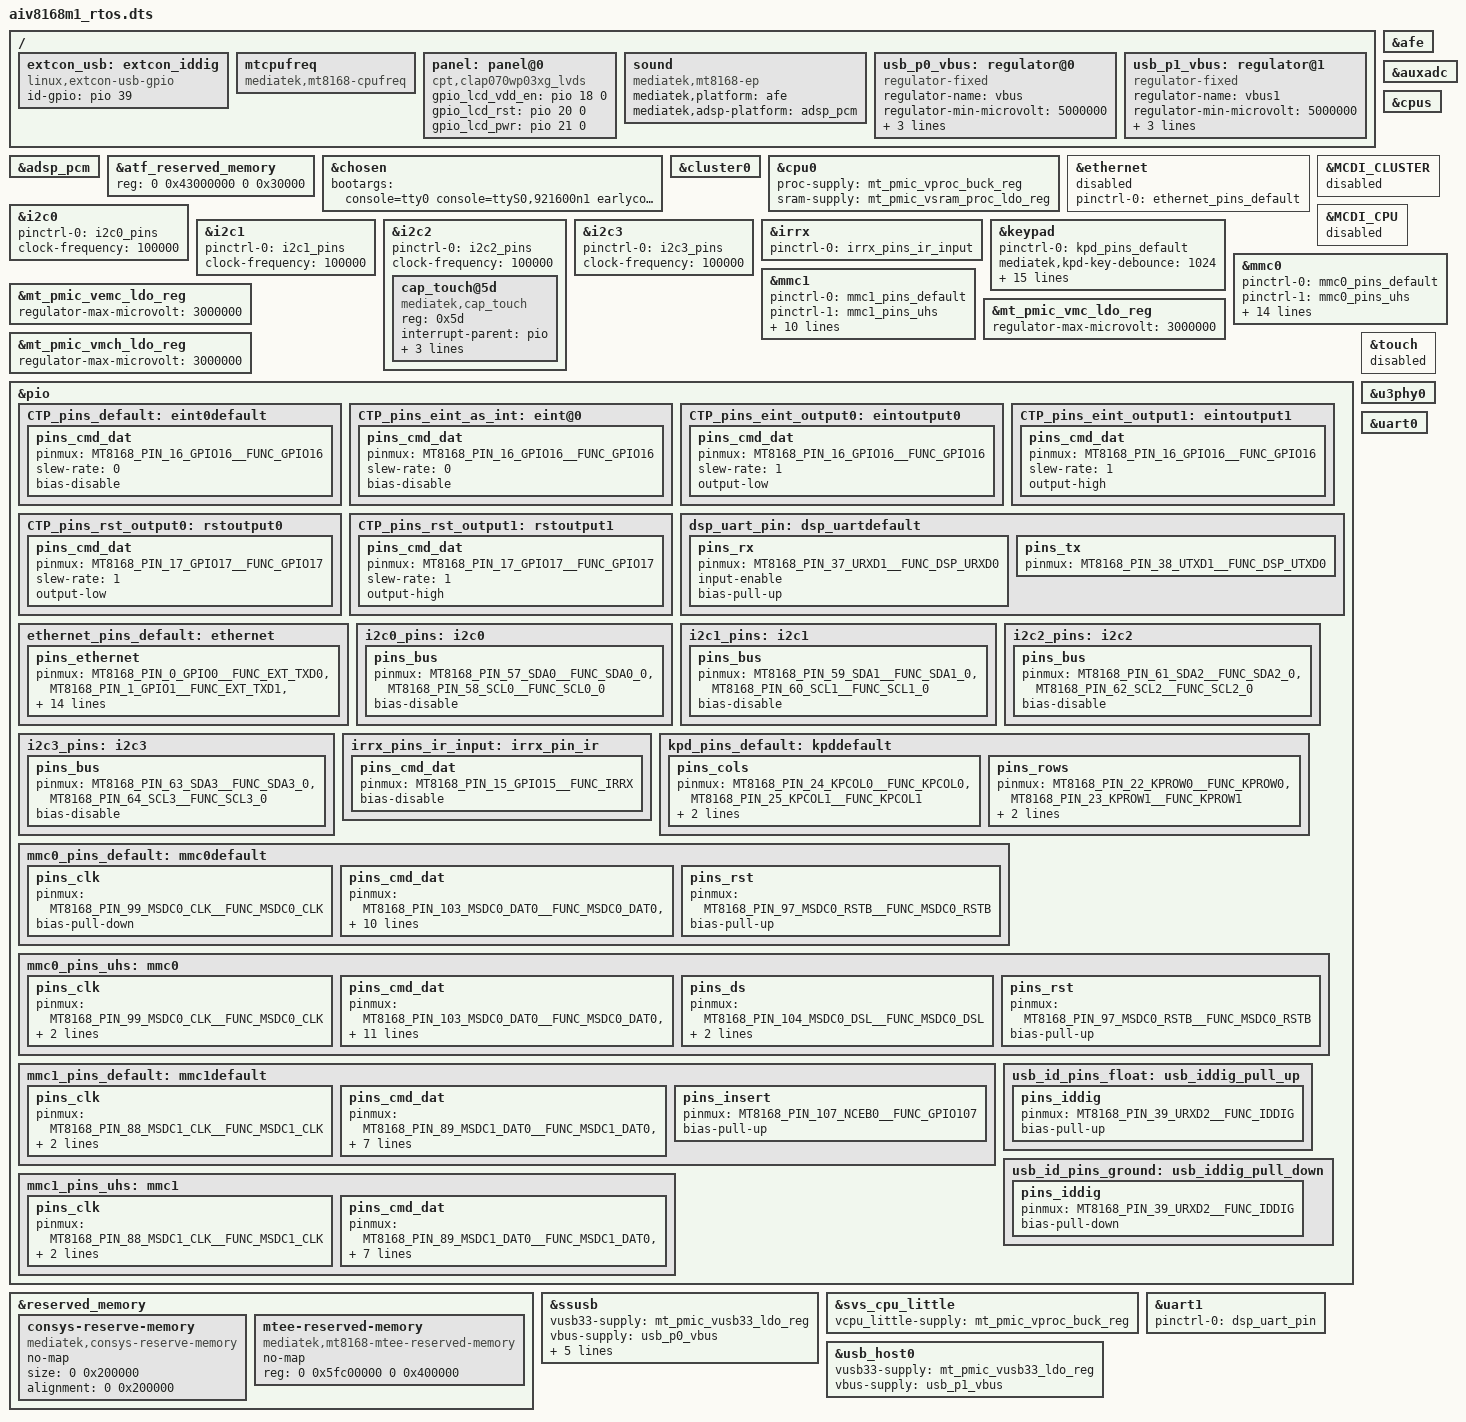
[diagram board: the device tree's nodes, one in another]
/*
 * Copyright (c) 2019 MediaTek Inc.
 *
 * This program is free software; you can redistribute it and/or modify
 * it under the terms of the GNU General Public License version 2 as
 * published by the Free Software Foundation.
 *
 * This program is distributed in the hope that it will be useful,
 * MERCHANTABILITY or FITNESS FOR A PARTICULAR PURPOSE.  See the
 * GNU General Public License for more details.
 */

/dts-v1/;
#include <dt-bindings/gpio/gpio.h>
#include "mt8168.dtsi"
#include "mt6357.dtsi"

/ {
	extcon_usb: extcon_iddig {
		compatible = "linux,extcon-usb-gpio";
		id-gpio = <&pio 39 GPIO_ACTIVE_HIGH>;
	};

	mtcpufreq {
		compatible = "mediatek,mt8168-cpufreq";
	};

	panel: panel@0 {
		compatible = "cpt,clap070wp03xg_lvds";
		gpio_lcd_vdd_en = <&pio 18 0>;
		gpio_lcd_rst = <&pio 20 0>;
		gpio_lcd_pwr = <&pio 21 0>;
		/*reg-lcm-supply = <&mt6392_vgp2_reg>;*/
	};

	sound: sound {
		compatible = "mediatek,mt8168-ep";
		mediatek,platform = <&afe>;
		mediatek,adsp-platform = <&adsp_pcm>;
		status = "okay";
	};

	usb_p0_vbus: regulator@0 {
		compatible = "regulator-fixed";
		regulator-name = "vbus";
		regulator-min-microvolt = <5000000>;
		regulator-max-microvolt = <5000000>;
		gpio = <&pio 40 GPIO_ACTIVE_HIGH>;
		enable-active-high;
	};

	usb_p1_vbus: regulator@1 {
		compatible = "regulator-fixed";
		regulator-name = "vbus1";
		regulator-min-microvolt = <5000000>;
		regulator-max-microvolt = <5000000>;
		enable-active-high;
		regulator-always-on;
	};
};

&adsp_pcm {
	status = "okay";
};

&afe {
	status = "okay";
};

&atf_reserved_memory {
	reg = <0 0x43000000 0 0x30000>;
};

&auxadc {
	status = "okay";
};

&chosen {
	bootargs = "console=tty0 console=ttyS0,921600n1 \
		    earlycon=uart8250,mmio32,0x11002000 vmalloc=496M \
		    clk_ignore_unused pd_ignore_unused \
		    skip_initramfs rootwait ro init=/sbin/init \
		    root=PARTUUID=936e1662-2b63-435d-859d-1b9e5a838335 \
		    boot_reason=0";
};

&cluster0 {
	/delete-node/ core1;
	/delete-node/ core2;
	/delete-node/ core3;
};

&cpus {
	/delete-node/ cpu@1;
	/delete-node/ cpu@2;
	/delete-node/ cpu@3;
};

&cpu0 {
	proc-supply = <&mt_pmic_vproc_buck_reg>;
	sram-supply = <&mt_pmic_vsram_proc_ldo_reg>;
};

&ethernet {
	status = "disabled";
	pinctrl-names = "default";
	pinctrl-0 = <&ethernet_pins_default>;
};

&i2c0 {
	pinctrl-names = "default";
	pinctrl-0 = <&i2c0_pins>;
	clock-frequency = <100000>;
	status = "okay";
};

&i2c1 {
	pinctrl-names = "default";
	pinctrl-0 = <&i2c1_pins>;
	clock-frequency = <100000>;
	status = "okay";
};

&i2c2 {
	pinctrl-names = "default";
	pinctrl-0 = <&i2c2_pins>;
	clock-frequency = <100000>;
	status = "okay";

	cap_touch@5d {
		compatible = "mediatek,cap_touch";
		reg = <0x5d>;
		interrupt-parent = <&pio>;
		interrupts = <16 IRQ_TYPE_EDGE_FALLING>;
		int-gpio = <&pio 16 0>;
		rst-gpio = <&pio 17 0>;
	};
};

&i2c3 {
	pinctrl-names = "default";
	pinctrl-0 = <&i2c3_pins>;
	clock-frequency = <100000>;
	status = "okay";
};

&irrx {
	pinctrl-names = "default";
	pinctrl-0 = <&irrx_pins_ir_input>;
	status = "okay";
};

&keypad {
	pinctrl-names = "default";
	pinctrl-0 = <&kpd_pins_default>;
	status = "okay";
	mediatek,kpd-key-debounce = <1024>;
	mediatek,kpd-sw-pwrkey = <116>;
	mediatek,kpd-hw-pwrkey = <1>;
	mediatek,kpd-sw-rstkey  = <114>;
	mediatek,kpd-hw-rstkey = <3>;
	mediatek,kpd-use-extend-type = <0>;
	/*HW Keycode [0~3] -> Linux Keycode*/
	mediatek,kpd-hw-map-num = <72>;
	mediatek,kpd-hw-init-map =
			<115 0 0 0 0 0 0 0 0 0 0 0 0
			 0 0 0 0 0 0 0 0 0 0 0 0 0 0 0 0 0 0 0 0 0 0 0 0
			 0 0 0 0 0 0 0 0 0 0 0 0 0 0 0 0 0 0 0 0 0 0 0 0
			 0 0 0 0 0 0 0 0 0 0 0 >;
	mediatek,kpd-pwrkey-eint-gpio = <0>;
	mediatek,kpd-pwkey-gpio-din  = <0>;
	mediatek,kpd-hw-dl-key0 = <0>;
	mediatek,kpd-hw-dl-key1 = <3>;
	mediatek,kpd-hw-dl-key2 = <1>;
	mediatek,kpd-hw-recovery-key = <0>;
	mediatek,kpd-hw-factory-key  = <3>;
};

&MCDI_CLUSTER {
	status = "disabled";
};

&MCDI_CPU {
	status = "disabled";
};

&mmc0 {
	status = "okay";
	pinctrl-names = "default", "state_uhs";
	pinctrl-0 = <&mmc0_pins_default>;
	pinctrl-1 = <&mmc0_pins_uhs>;
	bus-width = <8>;
	max-frequency = <200000000>;
	cap-mmc-highspeed;
	mmc-hs200-1_8v;
	mmc-hs400-1_8v;
	hs400-ds-delay = <0x12012>;
	vmmc-supply = <&mt_pmic_vemc_ldo_reg>;
	vqmmc-supply = <&mt_pmic_vio18_ldo_reg>;
	assigned-clocks = <&topckgen CLK_TOP_MSDC50_0_SEL>;
	assigned-clock-parents = <&topckgen CLK_TOP_MSDCPLL>;
	non-removable;
	no-sd;
	no-sdio;
};

&mmc1 {
	status = "okay";
	pinctrl-names = "default", "state_uhs";
	pinctrl-0 = <&mmc1_pins_default>;
	pinctrl-1 = <&mmc1_pins_uhs>;
	bus-width = <4>;
	max-frequency = <200000000>;
	cap-sd-highspeed;
	sd-uhs-sdr50;
	sd-uhs-sdr104;
	cd-gpios = <&pio 107 GPIO_ACTIVE_LOW>;
	vmmc-supply = <&mt_pmic_vmch_ldo_reg>;
	vqmmc-supply = <&mt_pmic_vmc_ldo_reg>;
	no-mmc;
	no-sdio;
};

&mt_pmic_vemc_ldo_reg {
	regulator-max-microvolt = <3000000>;
};

&mt_pmic_vmc_ldo_reg {
	regulator-max-microvolt = <3000000>;
};

&mt_pmic_vmch_ldo_reg {
	regulator-max-microvolt = <3000000>;
};

&pio {
	pinctrl-names = "default";

	CTP_pins_default: eint0default {
		pins_cmd_dat {
			pinmux = <MT8168_PIN_16_GPIO16__FUNC_GPIO16>;
			slew-rate = <0>;
			bias-disable;
		};
	};

	CTP_pins_eint_as_int: eint@0 {
		pins_cmd_dat {
			pinmux = <MT8168_PIN_16_GPIO16__FUNC_GPIO16>;
			slew-rate = <0>;
			bias-disable;
		};
	};

	CTP_pins_eint_output0: eintoutput0 {
		pins_cmd_dat {
			pinmux = <MT8168_PIN_16_GPIO16__FUNC_GPIO16>;
			slew-rate = <1>;
			output-low;
		};
	};

	CTP_pins_eint_output1: eintoutput1 {
		pins_cmd_dat {
			pinmux = <MT8168_PIN_16_GPIO16__FUNC_GPIO16>;
			slew-rate = <1>;
			output-high;
		};
	};

	CTP_pins_rst_output0: rstoutput0 {
		pins_cmd_dat {
			pinmux = <MT8168_PIN_17_GPIO17__FUNC_GPIO17>;
			slew-rate = <1>;
			output-low;
		};
	};

	CTP_pins_rst_output1: rstoutput1 {
		pins_cmd_dat {
			pinmux = <MT8168_PIN_17_GPIO17__FUNC_GPIO17>;
			slew-rate = <1>;
			output-high;
		};
	};

	dsp_uart_pin: dsp_uartdefault {
		pins_rx {
			pinmux = <MT8168_PIN_37_URXD1__FUNC_DSP_URXD0>;
			input-enable;
			bias-pull-up;
		};
		pins_tx {
			pinmux = <MT8168_PIN_38_UTXD1__FUNC_DSP_UTXD0>;
		};
	};

	ethernet_pins_default: ethernet {
		pins_ethernet {
			pinmux = <MT8168_PIN_0_GPIO0__FUNC_EXT_TXD0>,
				 <MT8168_PIN_1_GPIO1__FUNC_EXT_TXD1>,
				 <MT8168_PIN_2_GPIO2__FUNC_EXT_TXD2>,
				 <MT8168_PIN_3_GPIO3__FUNC_EXT_TXD3>,
				 <MT8168_PIN_4_GPIO4__FUNC_EXT_TXC>,
				 <MT8168_PIN_5_GPIO5__FUNC_EXT_RXER>,
				 <MT8168_PIN_6_GPIO6__FUNC_EXT_RXC>,
				 <MT8168_PIN_7_GPIO7__FUNC_EXT_RXDV>,
				 <MT8168_PIN_8_GPIO8__FUNC_EXT_RXD0>,
				 <MT8168_PIN_9_GPIO9__FUNC_EXT_RXD1>,
				 <MT8168_PIN_10_GPIO10__FUNC_EXT_RXD2>,
				 <MT8168_PIN_11_GPIO11__FUNC_EXT_RXD3>,
				 <MT8168_PIN_12_GPIO12__FUNC_EXT_TXEN>,
				 <MT8168_PIN_13_GPIO13__FUNC_EXT_COL>,
				 <MT8168_PIN_14_GPIO14__FUNC_EXT_MDIO>,
				 <MT8168_PIN_15_GPIO15__FUNC_EXT_MDC>;
		};
	};

	i2c0_pins: i2c0 {
		pins_bus {
			pinmux = <MT8168_PIN_57_SDA0__FUNC_SDA0_0>,
				 <MT8168_PIN_58_SCL0__FUNC_SCL0_0>;
			bias-disable;
		};
	};

	i2c1_pins: i2c1 {
		pins_bus {
			pinmux = <MT8168_PIN_59_SDA1__FUNC_SDA1_0>,
				 <MT8168_PIN_60_SCL1__FUNC_SCL1_0>;
			bias-disable;
		};
	};

	i2c2_pins: i2c2 {
		pins_bus {
			pinmux = <MT8168_PIN_61_SDA2__FUNC_SDA2_0>,
				 <MT8168_PIN_62_SCL2__FUNC_SCL2_0>;
			bias-disable;
		};
	};

	i2c3_pins: i2c3 {
		pins_bus {
			pinmux = <MT8168_PIN_63_SDA3__FUNC_SDA3_0>,
				 <MT8168_PIN_64_SCL3__FUNC_SCL3_0>;
			bias-disable;
		};
	};

	irrx_pins_ir_input: irrx_pin_ir {
		pins_cmd_dat {
			pinmux = <MT8168_PIN_15_GPIO15__FUNC_IRRX>;
			bias-disable;
		};
	};

	kpd_pins_default: kpddefault {
		pins_cols {
			pinmux = <MT8168_PIN_24_KPCOL0__FUNC_KPCOL0>,
				 <MT8168_PIN_25_KPCOL1__FUNC_KPCOL1>;
			input-enable;
			bias-pull-up = <MTK_PUPD_SET_R1R0_01>;
		};

		pins_rows {
			pinmux = <MT8168_PIN_22_KPROW0__FUNC_KPROW0>,
				 <MT8168_PIN_23_KPROW1__FUNC_KPROW1>;
			output-low;
			bias-disable;
		};
	};

	mmc0_pins_default: mmc0default {
		pins_clk {
			pinmux = <MT8168_PIN_99_MSDC0_CLK__FUNC_MSDC0_CLK>;
			bias-pull-down;
		};

		pins_cmd_dat {
			pinmux = <MT8168_PIN_103_MSDC0_DAT0__FUNC_MSDC0_DAT0>,
				 <MT8168_PIN_102_MSDC0_DAT1__FUNC_MSDC0_DAT1>,
				 <MT8168_PIN_101_MSDC0_DAT2__FUNC_MSDC0_DAT2>,
				 <MT8168_PIN_100_MSDC0_DAT3__FUNC_MSDC0_DAT3>,
				 <MT8168_PIN_96_MSDC0_DAT4__FUNC_MSDC0_DAT4>,
				 <MT8168_PIN_95_MSDC0_DAT5__FUNC_MSDC0_DAT5>,
				 <MT8168_PIN_94_MSDC0_DAT6__FUNC_MSDC0_DAT6>,
				 <MT8168_PIN_93_MSDC0_DAT7__FUNC_MSDC0_DAT7>,
				 <MT8168_PIN_98_MSDC0_CMD__FUNC_MSDC0_CMD>;
			input-enable;
			bias-pull-up;
		};

		pins_rst {
			pinmux = <MT8168_PIN_97_MSDC0_RSTB__FUNC_MSDC0_RSTB>;
			bias-pull-up;
		};
	};

	mmc0_pins_uhs: mmc0 {
		pins_clk {
			pinmux = <MT8168_PIN_99_MSDC0_CLK__FUNC_MSDC0_CLK>;
			drive-strength = <MTK_DRIVE_6mA>;
			bias-pull-down = <MTK_PUPD_SET_R1R0_01>;
		};

		pins_cmd_dat {
			pinmux = <MT8168_PIN_103_MSDC0_DAT0__FUNC_MSDC0_DAT0>,
				 <MT8168_PIN_102_MSDC0_DAT1__FUNC_MSDC0_DAT1>,
				 <MT8168_PIN_101_MSDC0_DAT2__FUNC_MSDC0_DAT2>,
				 <MT8168_PIN_100_MSDC0_DAT3__FUNC_MSDC0_DAT3>,
				 <MT8168_PIN_96_MSDC0_DAT4__FUNC_MSDC0_DAT4>,
				 <MT8168_PIN_95_MSDC0_DAT5__FUNC_MSDC0_DAT5>,
				 <MT8168_PIN_94_MSDC0_DAT6__FUNC_MSDC0_DAT6>,
				 <MT8168_PIN_93_MSDC0_DAT7__FUNC_MSDC0_DAT7>,
				 <MT8168_PIN_98_MSDC0_CMD__FUNC_MSDC0_CMD>;
			input-enable;
			drive-strength = <MTK_DRIVE_6mA>;
			bias-pull-up = <MTK_PUPD_SET_R1R0_01>;
		};

		pins_ds {
			pinmux = <MT8168_PIN_104_MSDC0_DSL__FUNC_MSDC0_DSL>;
			drive-strength = <MTK_DRIVE_6mA>;
			bias-pull-down = <MTK_PUPD_SET_R1R0_10>;
		};

		pins_rst {
			pinmux = <MT8168_PIN_97_MSDC0_RSTB__FUNC_MSDC0_RSTB>;
			bias-pull-up;
		};
	};

	mmc1_pins_default: mmc1default {
		pins_clk {
			pinmux = <MT8168_PIN_88_MSDC1_CLK__FUNC_MSDC1_CLK>;
			drive-strength = <MTK_DRIVE_4mA>;
			bias-pull-down = <MTK_PUPD_SET_R1R0_10>;
		};

		pins_cmd_dat {
			pinmux = <MT8168_PIN_89_MSDC1_DAT0__FUNC_MSDC1_DAT0>,
				 <MT8168_PIN_90_MSDC1_DAT1__FUNC_MSDC1_DAT1>,
				 <MT8168_PIN_91_MSDC1_DAT2__FUNC_MSDC1_DAT2>,
				 <MT8168_PIN_92_MSDC1_DAT3__FUNC_MSDC1_DAT3>,
				 <MT8168_PIN_87_MSDC1_CMD__FUNC_MSDC1_CMD>;
			input-enable;
			drive-strength = <MTK_DRIVE_4mA>;
			bias-pull-up = <MTK_PUPD_SET_R1R0_01>;
		};

		pins_insert {
			pinmux = <MT8168_PIN_107_NCEB0__FUNC_GPIO107>;
			bias-pull-up;
		};
	};

	mmc1_pins_uhs: mmc1 {
		pins_clk {
			pinmux = <MT8168_PIN_88_MSDC1_CLK__FUNC_MSDC1_CLK>;
			drive-strength = <MTK_DRIVE_6mA>;
			bias-pull-down = <MTK_PUPD_SET_R1R0_10>;
		};

		pins_cmd_dat {
			pinmux = <MT8168_PIN_89_MSDC1_DAT0__FUNC_MSDC1_DAT0>,
				 <MT8168_PIN_90_MSDC1_DAT1__FUNC_MSDC1_DAT1>,
				 <MT8168_PIN_91_MSDC1_DAT2__FUNC_MSDC1_DAT2>,
				 <MT8168_PIN_92_MSDC1_DAT3__FUNC_MSDC1_DAT3>,
				 <MT8168_PIN_87_MSDC1_CMD__FUNC_MSDC1_CMD>;
			input-enable;
			drive-strength = <MTK_DRIVE_6mA>;
			bias-pull-up = <MTK_PUPD_SET_R1R0_01>;
		};
	};

	usb_id_pins_float: usb_iddig_pull_up {
		pins_iddig {
			pinmux = <MT8168_PIN_39_URXD2__FUNC_IDDIG>;
			bias-pull-up;
		};
	};

	usb_id_pins_ground: usb_iddig_pull_down {
		pins_iddig {
			pinmux = <MT8168_PIN_39_URXD2__FUNC_IDDIG>;
			bias-pull-down;
		};
	};
};

&reserved_memory {
	#address-cells = <2>;
	#size-cells = <2>;

	consys-reserve-memory {
		compatible = "mediatek,consys-reserve-memory";
		no-map;
		size = <0 0x200000>;
		alignment = <0 0x200000>;
	};

	mtee-reserved-memory {
		compatible = "mediatek,mt8168-mtee-reserved-memory";
		no-map;
		reg = <0 0x5fc00000 0 0x400000>;
	};
};

&ssusb {
	vusb33-supply = <&mt_pmic_vusb33_ldo_reg>;
	vbus-supply = <&usb_p0_vbus>;
	extcon = <&extcon_usb>;
	dr_mode = "peripheral";
	pinctrl-names = "default", "id_float", "id_ground";
	pinctrl-0 = <&usb_id_pins_float>;
	pinctrl-1 = <&usb_id_pins_float>;
	pinctrl-2 = <&usb_id_pins_ground>;
	status="okay";
};

&svs_cpu_little {
	vcpu_little-supply = <&mt_pmic_vproc_buck_reg>;
};

&touch {
	status = "disabled";
};

&u3phy0 {
	status="okay";
};

&uart0 {
	status="okay";
};

&uart1 {
	pinctrl-names = "default";
	pinctrl-0 = <&dsp_uart_pin>;
	status="okay";
};

&usb_host0 {
	vusb33-supply = <&mt_pmic_vusb33_ldo_reg>;
	vbus-supply = <&usb_p1_vbus>;
	status = "okay";
};
